# EFR32BG21B020F1024IM32 register map
Vendor: Silicon Labs; Series: EFR32; File version: B
Registers are 32-bit, read-write, reset 0x0 unless marked. A register's access mark holds for its fields unless they carry their own. Offsets are from the block's base; [hi:lo] are bit positions; {n}, {i} and the like mark numbered series; 'fields as' and 'values as' point back to an identical list.

## SMU_S — SMU_S Registers
Base 0x44008000
Same registers: SMU_NS 0x54008000
0x00 IPVERSION ro
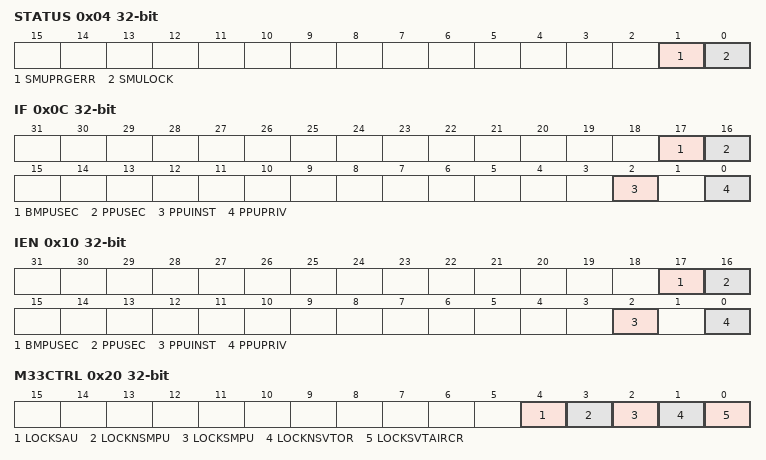
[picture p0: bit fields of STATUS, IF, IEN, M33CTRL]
0x04 STATUS ro
  [1] SMUPRGERR — SMU Programming Error
  [0] SMULOCK
    0=UNLOCKED; 1=LOCKED
0x08 LOCK wo
  [23:0] SMULOCKKEY
    0xACCE55=UNLOCK (Unlocks Registers)
0x0C IF
  [17] BMPUSEC — BMPU Security Interrupt Flag
  [16] PPUSEC — PPU Security Interrupt Flag
  [2] PPUINST — PPU Instruction Interrupt Flag
  [0] PPUPRIV — PPU Privilege Interrupt Flag
0x10 IEN
  fields as IF
0x20 M33CTRL — Holds the M33 control settings
  [4] LOCKSAU — SAU LOCK bit
  [3] LOCKNSMPU — NSMPU LOCK bit
  [2] LOCKSMPU — SMPU LOCK bit
  [1] LOCKNSVTOR — NSVTOR LOCK bit
  [0] LOCKSVTAIRCR — SVTAIRCR LOCK bit
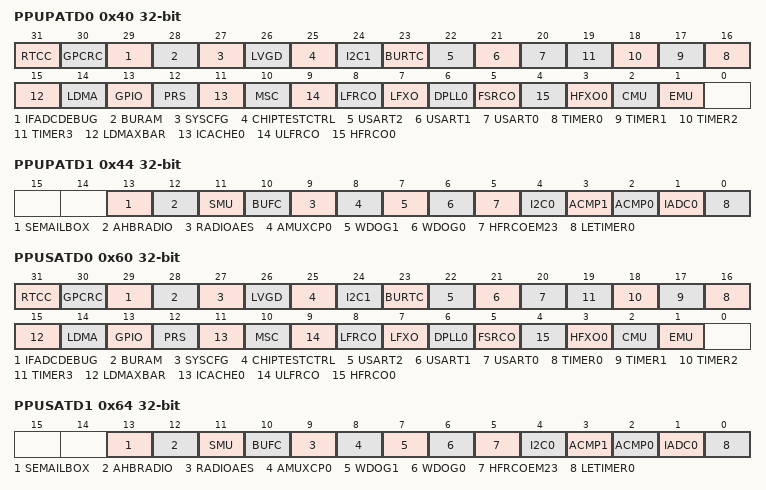
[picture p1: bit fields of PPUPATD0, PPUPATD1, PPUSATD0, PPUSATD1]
0x40 PPUPATD0 — Set peripheral bits to 1 to mark as privileged access only
  [31] RTCC — RTCC Privileged Access
  [30] GPCRC — GPCRC Privileged Access
  [29] IFADCDEBUG — IFADCDEBUG Privileged Access
  [28] BURAM — BURAM Privileged Access
  [27] SYSCFG — SYSCFG Privileged Access
  [26] LVGD — LVGD Privileged Access
  [25] CHIPTESTCTRL — CHIPTESTCTRL Privileged Access
  [24] I2C1 — I2C1 Privileged Access
  [23] BURTC — BURTC Privileged Access
  [22] USART2 — USART2 Privileged Access
  [21] USART1 — USART1 Privileged Access
  [20] USART0 — USART0 Privileged Access
  [n+16] TIMER{n} (n=0..3) — TIMER{n} Privileged Access
  [15] LDMAXBAR — LDMAXBAR Privileged Access
  [14] LDMA — LDMA Privileged Access
  [13] GPIO — GPIO Privileged Access
  [12] PRS — PRS Privileged Access
  [11] ICACHE0 — ICACHE0 Privileged Access
  [10] MSC — MSC Privileged Access
  [9] ULFRCO — ULFRCO Privileged Access
  [8] LFRCO — LFRCO Privileged Access
  [7] LFXO — LFXO Privileged Access
  [6] DPLL0 — DPLL0 Privileged Access
  [5] FSRCO — FSRCO Privileged Access
  [4] HFRCO0 — HFRCO0 Privileged Access
  [3] HFXO0 — HFXO0 Privileged Access
  [2] CMU — CMU Privileged Access
  [1] EMU — EMU Privileged Access
0x44 PPUPATD1 — Set peripheral bits to 1 to mark as privileged access only
  [13] SEMAILBOX — SE MAILBOX Privileged Access
  [12] AHBRADIO — AHBRADIO Privileged Access
  [11] SMU — SMU Privileged Access
  [10] BUFC — BUFC Privileged Access
  [9] RADIOAES — RADIOAES Privileged Access
  [8] AMUXCP0 — AMUXCP0 Privileged Access
  [7] WDOG1 — WDOG1 Privileged Access
  [6] WDOG0 — WDOG0 Privileged Access
  [5] HFRCOEM23 — HFRCOEM23 Privileged Access
  [4] I2C0 — I2C0 Privileged Access
  [3] ACMP1 — ACMP1 Privileged Access
  [2] ACMP0 — ACMP0 Privileged Access
  [1] IADC0 — IADC0 Privileged Access
  [0] LETIMER0 — LETIMER0 Privileged Access
0x60 PPUSATD0
  [31] RTCC — RTCC Secure Access
  [30] GPCRC — GPCRC Secure Access
  [29] IFADCDEBUG — IFADCDEBUG Secure Access
  [28] BURAM — BURAM Secure Access
  [27] SYSCFG — SYSCFG Secure Access
  [26] LVGD — LVGD Secure Access
  [25] CHIPTESTCTRL — CHIPTESTCTRL Secure Access
  [24] I2C1 — I2C1 Secure Access
  [23] BURTC — BURTC Secure Access
  [22] USART2 — USART2 Secure Access
  [21] USART1 — USART1 Secure Access
  [20] USART0 — USART0 Secure Access
  [n+16] TIMER{n} (n=0..3) — TIMER{n} Secure Access
  [15] LDMAXBAR — LDMAXBAR Secure Access
  [14] LDMA — LDMA Secure Access
  [13] GPIO — GPIO Secure Access
  [12] PRS — PRS Secure Access
  [11] ICACHE0 — ICACHE0 Secure Access
  [10] MSC — MSC Secure Access
  [9] ULFRCO — ULFRCO Secure Access
  [8] LFRCO — LFRCO Secure Access
  [7] LFXO — LFXO Secure Access
  [6] DPLL0 — DPLL0 Secure Access
  [5] FSRCO — FSRCO Secure Access
  [4] HFRCO0 — HFRCO0 Secure Access
  [3] HFXO0 — HFXO0 Secure Access
  [2] CMU — CMU Secure Access
  [1] EMU — EMU Secure Access
0x64 PPUSATD1
  [13] SEMAILBOX — SE MAILBOX Secure Access
  [12] AHBRADIO — AHBRADIO Secure Access
  [11] SMU — SMU Secure Access
  [10] BUFC — BUFC Secure Access
  [9] RADIOAES — RADIOAES Secure Access
  [8] AMUXCP0 — AMUXCP0 Secure Access
  [7] WDOG1 — WDOG1 Secure Access
  [6] WDOG0 — WDOG0 Secure Access
  [5] HFRCOEM23 — HFRCOEM23 Secure Access
  [4] I2C0 — I2C0 Secure Access
  [3] ACMP1 — ACMP1 Secure Access
  [2] ACMP0 — ACMP0 Secure Access
  [1] IADC0 — IADC0 Secure Access
  [0] LETIMER0 — LETIMER0 Secure Access
0x140 PPUFS ro
  [7:0] PPUFSPERIPHID — Peripheral ID
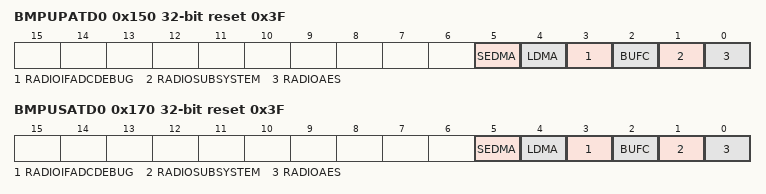
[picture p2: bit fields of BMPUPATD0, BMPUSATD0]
0x150 BMPUPATD0 reset 0x3F
  [5] SEDMA — SE mailbox DMA privileged mode
  [4] LDMA — MCU LDMA privileged mode
  [3] RADIOIFADCDEBUG — RADIO IFADC debug privileged mode
  [2] BUFC — RADIO BUFFER controller privileged mode
  [1] RADIOSUBSYSTEM — RADIO subsystem masters privileged mode
  [0] RADIOAES — RADIO AES DMA privileged mode
0x170 BMPUSATD0 reset 0x3F
  [5] SEDMA — MCU to SE mailbox DMA secure mode
  [4] LDMA — MCU LDMA secure mode
  [3] RADIOIFADCDEBUG — RADIO IFADC debug secure mode
  [2] BUFC — RADIO BUFFER controller secure mode
  [1] RADIOSUBSYSTEM — RADIO subsystem masters secure mode
  [0] RADIOAES — RADIO AES DMA secure mode
0x250 BMPUFS ro
  [7:0] BMPUFSMASTERID — Master ID
0x254 BMPUFSADDR ro
  [31:0] BMPUFSADDR — Fault Address
0x260 ESAURTYPES0
  [12] ESAUR3NS — Region 3 Non-Secure
0x264 ESAURTYPES1
  [12] ESAUR11NS — Region 11 Non-Secure
0x270 ESAUMRB01 reset 0x2000000
  [27:12] ESAUMRB01 — Moveable Region Boundary
0x274 ESAUMRB12 reset 0x4000000
  [27:12] ESAUMRB12 — Moveable Region Boundary
0x280 ESAUMRB45 reset 0x2000000
  [27:12] ESAUMRB45 — Moveable Region Boundary
0x284 ESAUMRB56 reset 0x4000000
  [27:12] ESAUMRB56 — Moveable Region Boundary
